# STM32L053 register map
File version: 1.0
CPU: CM0+ r0p0, little endian, MPU, no FPU, 4 interrupt priority bits
Registers are 32-bit, read-write, reset 0x0 unless marked. A register's access mark holds for its fields unless they carry their own. Offsets are from the block's base; [hi:lo] are bit positions; lines under a group give offsets from that group; {n}, {i} and the like mark numbered series; 'fields as' and 'values as' point back to an identical list.

## RNG — Random number generator
Base 0x40025000
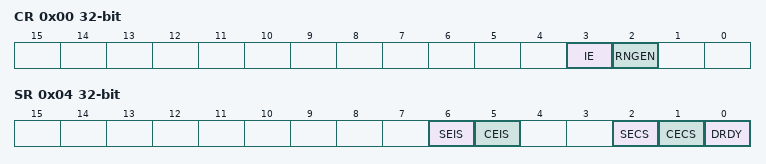
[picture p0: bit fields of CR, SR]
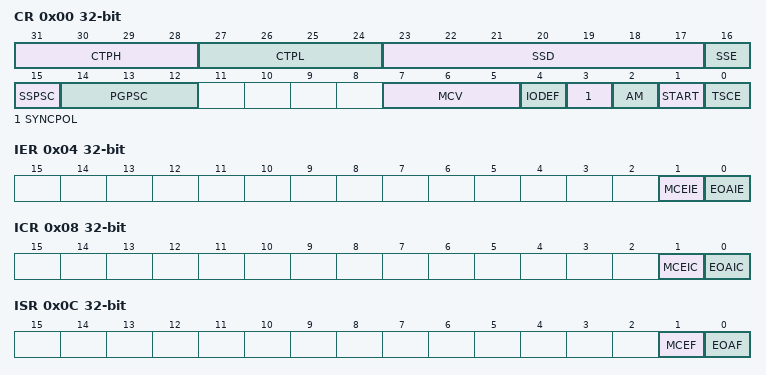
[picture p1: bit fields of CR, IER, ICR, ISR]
0x00 CR — control register
  [3] IE — Interrupt enable
  [2] RNGEN — Random number generator enable
0x04 SR access per field — status register
  [6] SEIS rw — Seed error interrupt status
  [5] CEIS rw — Clock error interrupt status
  [2] SECS ro — Seed error current status
  [1] CECS ro — Clock error current status
  [0] DRDY ro — Data ready
0x08 DR ro — data register
  [31:0] RNDATA — Random data

## TSC — Touch sensing controller
Base 0x40024000
0x00 CR — control register
  [31:28] CTPH — Charge transfer pulse high
  [27:24] CTPL — Charge transfer pulse low
  [23:17] SSD — Spread spectrum deviation
  [16] SSE — Spread spectrum enable
  [15] SSPSC — Spread spectrum prescaler
  [14:12] PGPSC — pulse generator prescaler
  [7:5] MCV — Max count value
  [4] IODEF — I/O Default mode
  [3] SYNCPOL — Synchronization pin polarity
  [2] AM — Acquisition mode
  [1] START — Start a new acquisition
  [0] TSCE — Touch sensing controller enable
0x04 IER — interrupt enable register
  [1] MCEIE — Max count error interrupt enable
  [0] EOAIE — End of acquisition interrupt enable
0x08 ICR — interrupt clear register
  [1] MCEIC — Max count error interrupt clear
  [0] EOAIC — End of acquisition interrupt clear
0x0C ISR — interrupt status register
  [1] MCEF — Max count error flag
  [0] EOAF — End of acquisition flag
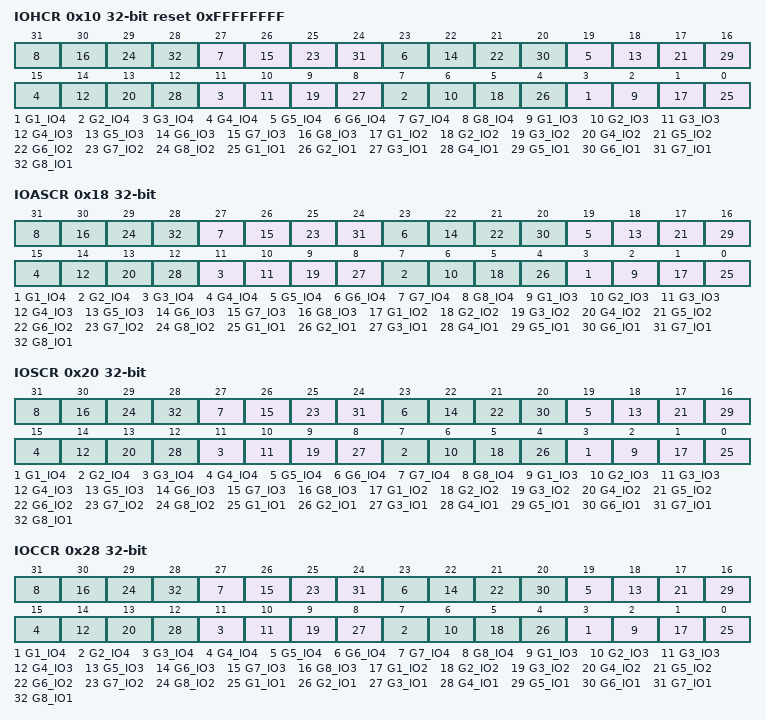
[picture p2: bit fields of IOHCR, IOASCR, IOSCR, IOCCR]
0x10 IOHCR reset 0xFFFFFFFF — I/O hysteresis control register
  [4n-1] G{n}_IO4 (n=1..8), [4n-2] G{n}_IO3 (n=1..8), [4n-3] G{n}_IO2 (n=1..8), [4n-4] G{n}_IO1 (n=1..8)
0x18 IOASCR — I/O analog switch control register
  fields as IOHCR
0x20 IOSCR — I/O sampling control register
  fields as IOHCR
0x28 IOCCR — I/O channel control register
  fields as IOHCR
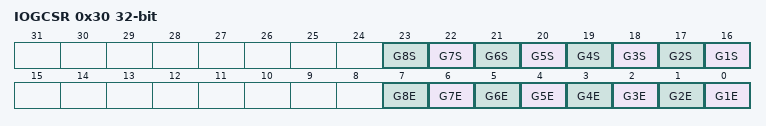
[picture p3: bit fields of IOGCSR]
0x30 IOGCSR access per field — I/O group control status register
  [n+15] G{n}S ro (n=1..8) — Analog I/O group x status
  [n-1] G{n}E rw (n=1..8) — Analog I/O group x enable
{0x30+4i} IOG{i}CR ro (i=1..8) — I/O group x counter register
  [13:0] CNT — Counter value

## IWDG — Independent watchdog
Base 0x40003000
0x00 KR wo — Key register
  [15:0] KEY — Key value (write only, read 0x0000)
0x04 PR — Prescaler register
  [2:0] PR — Prescaler divider
0x08 RLR reset 0xFFF — Reload register
  [11:0] RL — Watchdog counter reload value
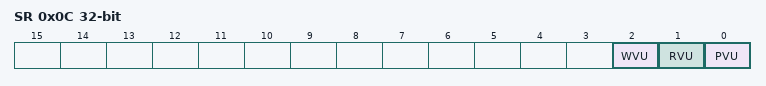
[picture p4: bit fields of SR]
0x0C SR ro — Status register
  [2] WVU — Watchdog counter window value update
  [1] RVU — Watchdog counter reload value update
  [0] PVU — Watchdog prescaler value update
0x10 WINR reset 0xFFF — Window register
  [11:0] WIN — Watchdog counter window value

## WWDG — System window watchdog
Base 0x40002C00
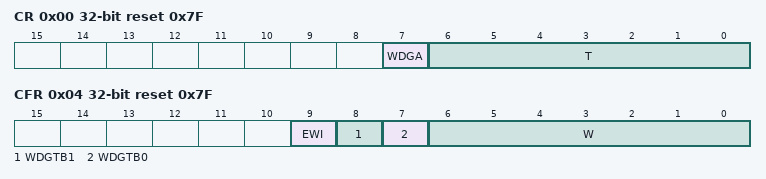
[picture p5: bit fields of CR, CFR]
0x00 CR reset 0x7F — Control register
  [7] WDGA — Activation bit
  [6:0] T — 7-bit counter (MSB to LSB)
0x04 CFR reset 0x7F — Configuration register
  [9] EWI — Early wakeup interrupt
  [8] WDGTB1 — Timer base
  [7] WDGTB0
  [6:0] W — 7-bit window value
0x08 SR — Status register
  [0] EWIF — Early wakeup interrupt flag

## USB_FS — Universal serial bus full-speed device interface
Base 0x40005C00
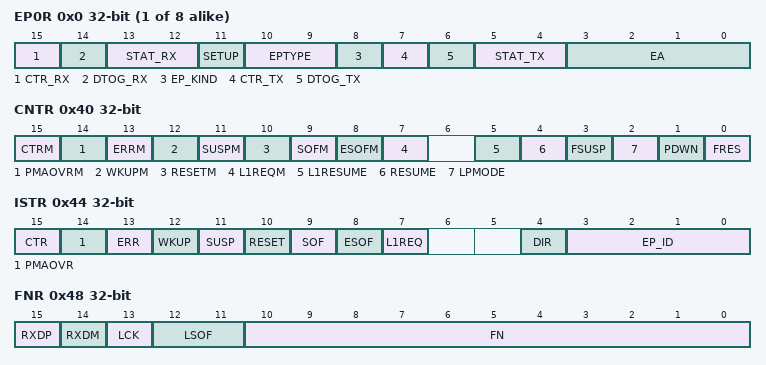
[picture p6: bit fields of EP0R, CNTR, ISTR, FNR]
{0x0+4i} EP{i}R (i=0..7) — endpoint register
  [15] CTR_RX, [14] DTOG_RX, [13:12] STAT_RX, [11] SETUP, [10:9] EPTYPE, [8] EP_KIND, [7] CTR_TX, [6] DTOG_TX, [5:4] STAT_TX, [3:0] EA
0x40 CNTR — control register
  [15] CTRM, [14] PMAOVRM, [13] ERRM, [12] WKUPM, [11] SUSPM, [10] RESETM, [9] SOFM, [8] ESOFM, [7] L1REQM, [5] L1RESUME, [4] RESUME, [3] FSUSP, [2] LPMODE, [1] PDWN, [0] FRES
0x44 ISTR — interrupt status register
  [15] CTR, [14] PMAOVR, [13] ERR, [12] WKUP, [11] SUSP, [10] RESET, [9] SOF, [8] ESOF, [7] L1REQ, [4] DIR, [3:0] EP_ID
0x48 FNR ro — frame number register
  [15] RXDP, [14] RXDM, [13] LCK, [12:11] LSOF, [10:0] FN
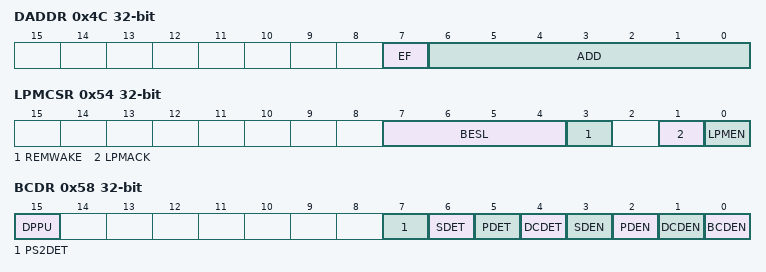
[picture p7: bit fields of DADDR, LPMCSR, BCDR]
0x4C DADDR — device address
  [7] EF, [6:0] ADD
0x50 BTABLE — Buffer table address
  [15:3] BTABLE
0x54 LPMCSR access per field — LPM control and status register
  [7:4] BESL ro, [3] REMWAKE ro, [1] LPMACK rw, [0] LPMEN rw
0x58 BCDR access per field — Battery charging detector
  [15] DPPU rw, [7] PS2DET ro, [6] SDET ro, [5] PDET ro, [4] DCDET ro, [3] SDEN rw, [2] PDEN rw, [1] DCDEN rw, [0] BCDEN rw
